# nrf54h20_engb_radiocore register map
Vendor: Nordic Semiconductor; Series: nRF54h; File version: 1
CPU: CM33 r0p4, little endian, MPU, FPU, 3 interrupt priority bits, 480 interrupts, 8 SAU regions
Registers are 32-bit, read-write, reset 0x0 unless marked. A register's access mark holds for its fields unless they carry their own. Offsets are from the block's base; [hi:lo] are bit positions; lines under a group give offsets from that group; {n}, {i} and the like mark numbered series.

## PPIB020_S — PPIB APB registers 0
Base 0x53023000
Same registers: PPIB030_S 0x53031000
{0x0+4i} TASKS_SEND[{i}] (i=0..31) wo — Description collection: This task is unused, but the PPIB provides the SUBSCRIBE task to connect SEND [n] task.
  [0] TASKS_SEND — This task is unused, but the PPIB provides the SUBSCRIBE task to connect SEND [n] task.
    1=Trigger task
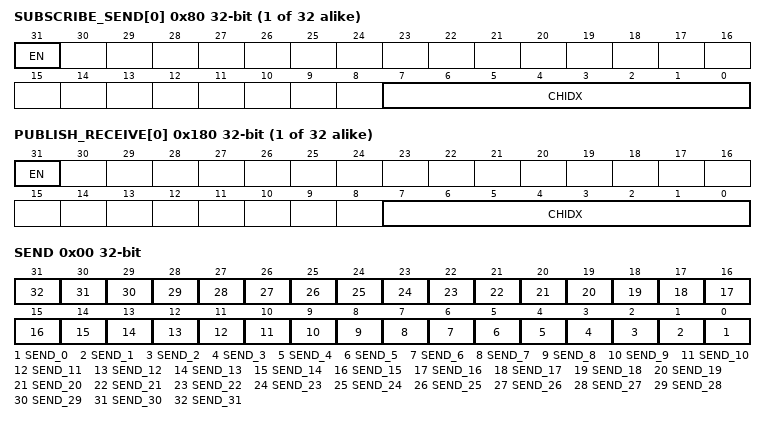
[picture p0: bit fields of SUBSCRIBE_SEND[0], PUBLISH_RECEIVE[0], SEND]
{0x80+4i} SUBSCRIBE_SEND[{i}] (i=0..31) — Description collection: Subscribe configuration for task SEND[n]
  [31] EN
    0=Disabled (Disable subscription); 1=Enabled (Enable subscription)
  [7:0] CHIDX — DPPI channel that task SEND[n] will subscribe to
{0x100+4i} EVENTS_RECEIVE[{i}] (i=0..31) — Description collection: This event is unused, but the PPIB provides the PUBLISH event to connect RECEIVE [n] event.
  [0] EVENTS_RECEIVE — This event is unused, but the PPIB provides the PUBLISH event to connect RECEIVE [n] event.
    0=NotGenerated (Event not generated); 1=Generated (Event generated)
{0x180+4i} PUBLISH_RECEIVE[{i}] (i=0..31) — Description collection: Publish configuration for event RECEIVE[n]
  [31] EN
    0=Disabled (Disable publishing); 1=Enabled (Enable publishing)
  [7:0] CHIDX — DPPI channel that event RECEIVE[n] will publish to
0x400 OVERFLOW group — Unspecified
  0x00 SEND — The task overflow for SEND tasks using SUBSCRIBE_SEND. Write 0 to clear.
    [all] fields
      1=Overflow (Task overflow is happened.); 0=NoOverflow (Task overflow is not happened.)
    [n] SEND_{n} (n=0..31) — The status for tasks overflow at SUBSCRIBE_SEND[{n}].

## EGU020_NS — Event generator unit 0
Base 0x43025000
Same registers: GLOBAL_EGU130_NS 0x4F92D000, EGU020_S 0x53025000, GLOBAL_EGU130_S 0x5F92D000
{0x0+4i} TASKS_TRIGGER[{i}] (i=0..15) wo — Description collection: Trigger n for triggering the corresponding TRIGGERED[n] event
  [0] TASKS_TRIGGER — Trigger n for triggering the corresponding TRIGGERED[n] event
    1=Trigger task
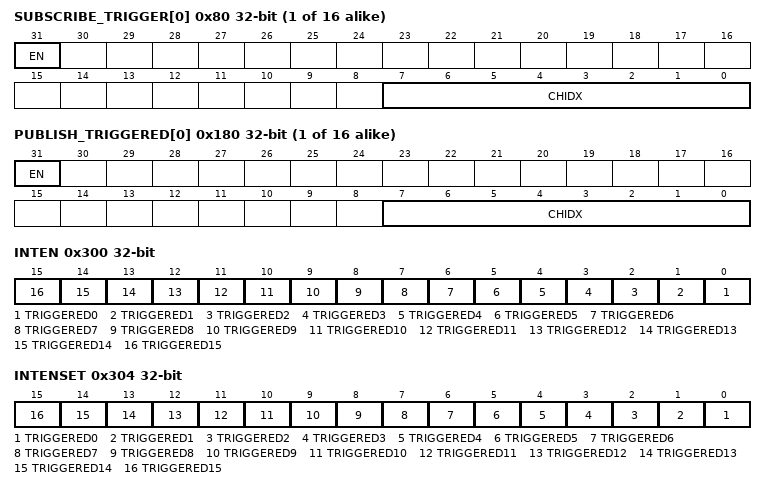
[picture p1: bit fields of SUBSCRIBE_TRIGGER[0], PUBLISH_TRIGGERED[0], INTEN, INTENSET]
{0x80+4i} SUBSCRIBE_TRIGGER[{i}] (i=0..15) — Description collection: Subscribe configuration for task TRIGGER[n]
  [31] EN
    0=Disabled (Disable subscription); 1=Enabled (Enable subscription)
  [7:0] CHIDX — DPPI channel that task TRIGGER[n] will subscribe to
{0x100+4i} EVENTS_TRIGGERED[{i}] (i=0..15) — Description collection: Event number n generated by triggering the corresponding TRIGGER[n] task
  [0] EVENTS_TRIGGERED — Event number n generated by triggering the corresponding TRIGGER[n] task
    0=NotGenerated (Event not generated); 1=Generated (Event generated)
{0x180+4i} PUBLISH_TRIGGERED[{i}] (i=0..15) — Description collection: Publish configuration for event TRIGGERED[n]
  [31] EN
    0=Disabled (Disable publishing); 1=Enabled (Enable publishing)
  [7:0] CHIDX — DPPI channel that event TRIGGERED[n] will publish to
0x300 INTEN — Enable or disable interrupt
  [all] fields
    0=Disabled; 1=Enabled
  [n] TRIGGERED{n} (n=0..15) — Enable or disable interrupt for event TRIGGERED[{n}]
0x304 INTENSET — Enable interrupt
  [all] fields
    on read: 0=Disabled (Read: Disabled); 1=Enabled (Read: Enabled) | on write: 1=Set (Enable)
  [n] TRIGGERED{n} (n=0..15) — Write '1' to enable interrupt for event TRIGGERED[{n}]
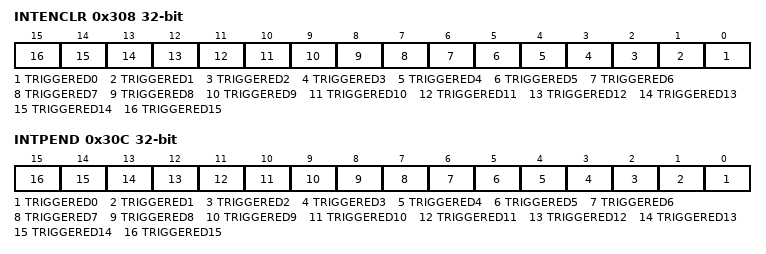
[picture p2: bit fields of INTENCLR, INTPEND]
0x308 INTENCLR — Disable interrupt
  [all] fields
    on read: 0=Disabled (Read: Disabled); 1=Enabled (Read: Enabled) | on write: 1=Clear (Disable)
  [n] TRIGGERED{n} (n=0..15) — Write '1' to disable interrupt for event TRIGGERED[{n}]
0x30C INTPEND ro — Pending interrupts
  [all] fields
    on read: 0=NotPending (Read: Not pending); 1=Pending (Read: Pending)
  [n] TRIGGERED{n} (n=0..15) — Read pending status of interrupt for event TRIGGERED[{n}]
